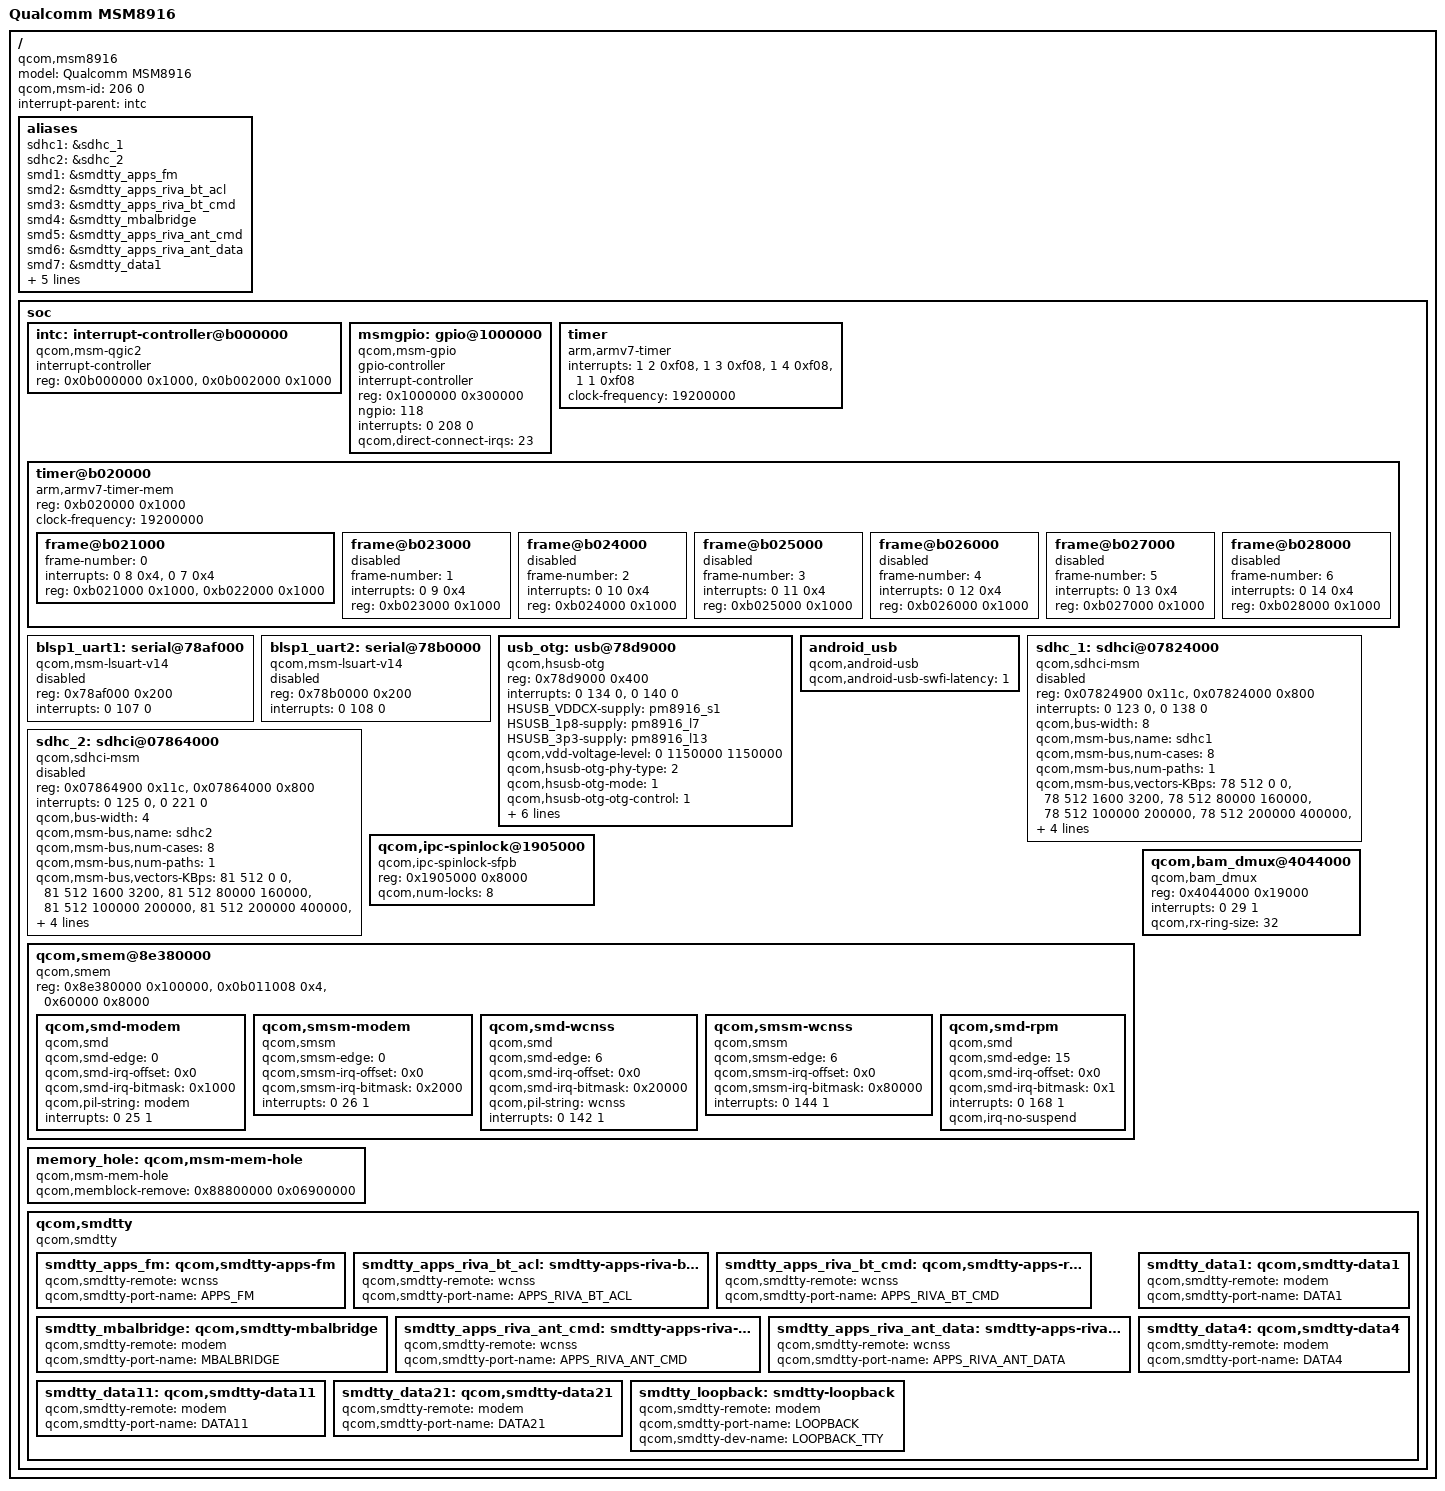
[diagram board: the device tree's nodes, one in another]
/* Copyright (c) 2013, The Linux Foundation. All rights reserved.
 *
 * This program is free software; you can redistribute it and/or modify
 * it under the terms of the GNU General Public License version 2 and
 * only version 2 as published by the Free Software Foundation.
 *
 * This program is distributed in the hope that it will be useful,
 * but WITHOUT ANY WARRANTY; without even the implied warranty of
 * MERCHANTABILITY or FITNESS FOR A PARTICULAR PURPOSE.  See the
 * GNU General Public License for more details.
 */

/include/ "skeleton.dtsi"

/ {
	model = "Qualcomm MSM8916";
	compatible = "qcom,msm8916";
	qcom,msm-id = <206 0>;

	interrupt-parent = <&intc>;
	aliases {
		sdhc1 = &sdhc_1; /* SDC1 eMMC slot */
		sdhc2 = &sdhc_2; /* SDC2 SD card slot */

		/* smdtty devices */
		smd1 = &smdtty_apps_fm;
		smd2 = &smdtty_apps_riva_bt_acl;
		smd3 = &smdtty_apps_riva_bt_cmd;
		smd4 = &smdtty_mbalbridge;
		smd5 = &smdtty_apps_riva_ant_cmd;
		smd6 = &smdtty_apps_riva_ant_data;
		smd7 = &smdtty_data1;
		smd8 = &smdtty_data4;
		smd11 = &smdtty_data11;
		smd21 = &smdtty_data21;
		smd27 = &smdtty_gps_nmea;
		smd36 = &smdtty_loopback;
	};
	soc: soc { };
};

/include/ "msm8916-ion.dtsi"
/include/ "msm8916-smp2p.dtsi"
/include/ "msm8916-ipcrouter.dtsi"

&soc {
	#address-cells = <1>;
	#size-cells = <1>;
	ranges;

	intc: interrupt-controller@b000000 {
		compatible = "qcom,msm-qgic2";
		interrupt-controller;
		#interrupt-cells = <3>;
		reg = <0x0b000000 0x1000>,
		<0x0b002000 0x1000>;
	};

	msmgpio: gpio@1000000 {
		compatible = "qcom,msm-gpio";
		gpio-controller;
		#gpio-cells = <2>;
		interrupt-controller;
		#interrupt-cells = <2>;
		reg = <0x1000000 0x300000>;
		ngpio = <118>;
		interrupts = <0 208 0>;
		qcom,direct-connect-irqs = <23>;
	};

	timer {
		compatible = "arm,armv7-timer";
		interrupts = <1 2 0xf08>,
			     <1 3 0xf08>,
			     <1 4 0xf08>,
			     <1 1 0xf08>;
		clock-frequency = <19200000>;
	};

	timer@b020000 {
		#address-cells = <1>;
		#size-cells = <1>;
		ranges;
		compatible = "arm,armv7-timer-mem";
		reg = <0xb020000 0x1000>;
		clock-frequency = <19200000>;

		frame@b021000 {
			frame-number = <0>;
			interrupts = <0 8 0x4>,
				     <0 7 0x4>;
			reg = <0xb021000 0x1000>,
			      <0xb022000 0x1000>;
		};

		frame@b023000 {
			frame-number = <1>;
			interrupts = <0 9 0x4>;
			reg = <0xb023000 0x1000>;
			status = "disabled";
		};

		frame@b024000 {
			frame-number = <2>;
			interrupts = <0 10 0x4>;
			reg = <0xb024000 0x1000>;
			status = "disabled";
		};

		frame@b025000 {
			frame-number = <3>;
			interrupts = <0 11 0x4>;
			reg = <0xb025000 0x1000>;
			status = "disabled";
		};

		frame@b026000 {
			frame-number = <4>;
			interrupts = <0 12 0x4>;
			reg = <0xb026000 0x1000>;
			status = "disabled";
		};

		frame@b027000 {
			frame-number = <5>;
			interrupts = <0 13 0x4>;
			reg = <0xb027000 0x1000>;
			status = "disabled";
		};

		frame@b028000 {
			frame-number = <6>;
			interrupts = <0 14 0x4>;
			reg = <0xb028000 0x1000>;
			status = "disabled";
		};
	};

	blsp1_uart1: serial@78af000 {
		compatible = "qcom,msm-lsuart-v14";
		reg = <0x78af000 0x200>;
		interrupts = <0 107 0>;
		status = "disabled";
	};

	blsp1_uart2: serial@78b0000 {
		compatible = "qcom,msm-lsuart-v14";
		reg = <0x78b0000 0x200>;
		interrupts = <0 108 0>;
		status = "disabled";
	};

	usb_otg: usb@78d9000 {
		compatible = "qcom,hsusb-otg";

		reg = <0x78d9000 0x400>;
		interrupts = <0 134 0>,<0 140 0>;
		interrupt-names = "core_irq", "async_irq";

		HSUSB_VDDCX-supply = <&pm8916_s1>;
		HSUSB_1p8-supply = <&pm8916_l7>;
		HSUSB_3p3-supply = <&pm8916_l13>;
		qcom,vdd-voltage-level = <0 1150000 1150000>;

		qcom,hsusb-otg-phy-type = <2>;
		qcom,hsusb-otg-mode = <1>;
		qcom,hsusb-otg-otg-control = <1>;
		qcom,hsusb-otg-disable-reset;

		qcom,msm-bus,name = "usb2";
		qcom,msm-bus,num-cases = <3>;
		qcom,msm-bus,num-paths = <1>;
		qcom,msm-bus,vectors-KBps =
				<87 512 0 0>,
				<87 512 60000 960000>,
				<87 512 6000  6000>;
	};

	android_usb {
		compatible = "qcom,android-usb";
		qcom,android-usb-swfi-latency = <1>;
	};

	sdhc_1: sdhci@07824000 {
		compatible = "qcom,sdhci-msm";
		reg = <0x07824900 0x11c>, <0x07824000 0x800>;
		reg-names = "hc_mem", "core_mem";

		interrupts = <0 123 0>, <0 138 0>;
		interrupt-names = "hc_irq", "pwr_irq";

		qcom,bus-width = <8>;

		qcom,msm-bus,name = "sdhc1";
		qcom,msm-bus,num-cases = <8>;
		qcom,msm-bus,num-paths = <1>;
		qcom,msm-bus,vectors-KBps = <78 512 0 0>, /* No vote */
				<78 512 1600 3200>,    /* 400 KB/s*/
				<78 512 80000 160000>, /* 20 MB/s */
				<78 512 100000 200000>, /* 25 MB/s */
				<78 512 200000 400000>, /* 50 MB/s */
				<78 512 400000 800000>, /* 100 MB/s */
				<78 512 400000 800000>, /* 200 MB/s */
				<78 512 2048000 4096000>; /* Max. bandwidth */
		qcom,bus-bw-vectors-bps = <0 400000 20000000 25000000 50000000
						100000000 200000000 4294967295>;
		status = "disabled";
	};

	sdhc_2: sdhci@07864000 {
		compatible = "qcom,sdhci-msm";
		reg = <0x07864900 0x11c>, <0x07864000 0x800>;
		reg-names = "hc_mem", "core_mem";

		interrupts = <0 125 0>, <0 221 0>;
		interrupt-names = "hc_irq", "pwr_irq";

		qcom,bus-width = <4>;

		qcom,msm-bus,name = "sdhc2";
		qcom,msm-bus,num-cases = <8>;
		qcom,msm-bus,num-paths = <1>;
		qcom,msm-bus,vectors-KBps = <81 512 0 0>, /* No vote */
				<81 512 1600 3200>,    /* 400 KB/s*/
				<81 512 80000 160000>, /* 20 MB/s */
				<81 512 100000 200000>, /* 25 MB/s */
				<81 512 200000 400000>, /* 50 MB/s */
				<81 512 400000 800000>, /* 100 MB/s */
				<81 512 400000 800000>, /* 200 MB/s */
				<81 512 2048000 4096000>; /* Max. bandwidth */
		qcom,bus-bw-vectors-bps = <0 400000 20000000 25000000 50000000
						100000000 200000000 4294967295>;
		status = "disabled";
	};

	qcom,ipc-spinlock@1905000 {
		compatible = "qcom,ipc-spinlock-sfpb";
		reg = <0x1905000 0x8000>;
		qcom,num-locks = <8>;
	};

	qcom,smem@8e380000 {
		compatible = "qcom,smem";
		reg = <0x8e380000 0x100000>,
			<0x0b011008 0x4>,
			<0x60000 0x8000>;
		reg-names = "smem", "irq-reg-base", "aux-mem1";

		qcom,smd-modem {
			compatible = "qcom,smd";
			qcom,smd-edge = <0>;
			qcom,smd-irq-offset = <0x0>;
			qcom,smd-irq-bitmask = <0x1000>;
			qcom,pil-string = "modem";
			interrupts = <0 25 1>;
		};

		qcom,smsm-modem {
			compatible = "qcom,smsm";
			qcom,smsm-edge = <0>;
			qcom,smsm-irq-offset = <0x0>;
			qcom,smsm-irq-bitmask = <0x2000>;
			interrupts = <0 26 1>;
		};

		qcom,smd-wcnss {
			compatible = "qcom,smd";
			qcom,smd-edge = <6>;
			qcom,smd-irq-offset = <0x0>;
			qcom,smd-irq-bitmask = <0x20000>;
			qcom,pil-string = "wcnss";
			interrupts = <0 142 1>;
		};

		qcom,smsm-wcnss {
			compatible = "qcom,smsm";
			qcom,smsm-edge = <6>;
			qcom,smsm-irq-offset = <0x0>;
			qcom,smsm-irq-bitmask = <0x80000>;
			interrupts = <0 144 1>;
		};

		qcom,smd-rpm {
			compatible = "qcom,smd";
			qcom,smd-edge = <15>;
			qcom,smd-irq-offset = <0x0>;
			qcom,smd-irq-bitmask = <0x1>;
			interrupts = <0 168 1>;
			qcom,irq-no-suspend;
		};
	};

	memory_hole: qcom,msm-mem-hole {
		compatible = "qcom,msm-mem-hole";
		qcom,memblock-remove = <0x88800000 0x06900000>;
	};

	qcom,bam_dmux@4044000 {
		compatible = "qcom,bam_dmux";
		reg = <0x4044000 0x19000>;
		interrupts = <0 29 1>;
		qcom,rx-ring-size = <32>;
	};

	qcom,smdtty {
		compatible = "qcom,smdtty";

		smdtty_apps_fm: qcom,smdtty-apps-fm {
			qcom,smdtty-remote = "wcnss";
			qcom,smdtty-port-name = "APPS_FM";
		};

		smdtty_apps_riva_bt_acl: smdtty-apps-riva-bt-acl {
			qcom,smdtty-remote = "wcnss";
			qcom,smdtty-port-name = "APPS_RIVA_BT_ACL";
		};

		smdtty_apps_riva_bt_cmd: qcom,smdtty-apps-riva-bt-cmd {
			qcom,smdtty-remote = "wcnss";
			qcom,smdtty-port-name = "APPS_RIVA_BT_CMD";
		};

		smdtty_mbalbridge: qcom,smdtty-mbalbridge {
			qcom,smdtty-remote = "modem";
			qcom,smdtty-port-name = "MBALBRIDGE";
		};

		smdtty_apps_riva_ant_cmd: smdtty-apps-riva-ant-cmd {
			qcom,smdtty-remote = "wcnss";
			qcom,smdtty-port-name = "APPS_RIVA_ANT_CMD";
		};

		smdtty_apps_riva_ant_data: smdtty-apps-riva-ant-data {
			qcom,smdtty-remote = "wcnss";
			qcom,smdtty-port-name = "APPS_RIVA_ANT_DATA";
		};

		smdtty_data1: qcom,smdtty-data1 {
			qcom,smdtty-remote = "modem";
			qcom,smdtty-port-name = "DATA1";
		};

		smdtty_data4: qcom,smdtty-data4 {
			qcom,smdtty-remote = "modem";
			qcom,smdtty-port-name = "DATA4";
		};

		smdtty_data11: qcom,smdtty-data11 {
			qcom,smdtty-remote = "modem";
			qcom,smdtty-port-name = "DATA11";
		};

		smdtty_data21: qcom,smdtty-data21 {
			qcom,smdtty-remote = "modem";
			qcom,smdtty-port-name = "DATA21";
		};

		smdtty_loopback: smdtty-loopback {
			qcom,smdtty-remote = "modem";
			qcom,smdtty-port-name = "LOOPBACK";
			qcom,smdtty-dev-name = "LOOPBACK_TTY";
		};
	};
};

/include/ "msm8916-regulator.dtsi"
